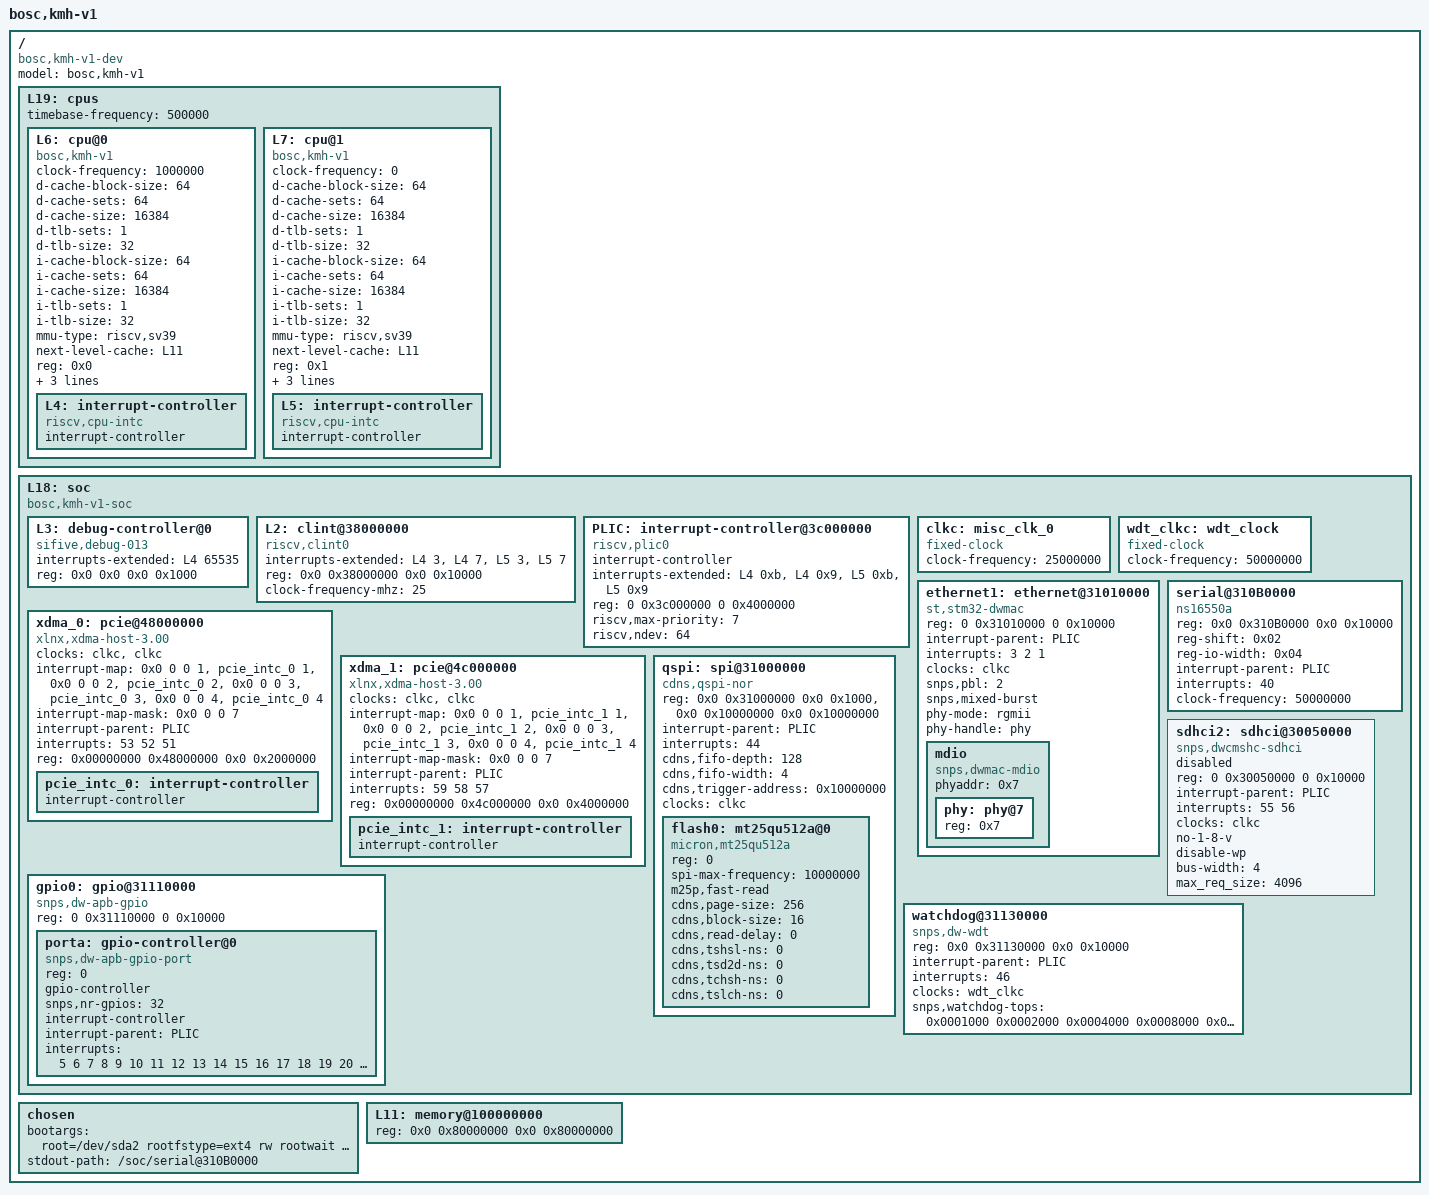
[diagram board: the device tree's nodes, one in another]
// SPDX-License-Identifier: (GPL-2.0 OR MIT)
/* Copyright (c) 2023-2024 BOSC */

/dts-v1/;

/ {
	#address-cells = <2>;
	#size-cells = <2>;
	compatible = "bosc,kmh-v1-dev";
	model = "bosc,kmh-v1";

	L19: cpus {
		#address-cells = <1>;
		#size-cells = <0>;
		timebase-frequency = <500000>;//50Khz

		L6: cpu@0 {
			clock-frequency = <1000000>;
			compatible = "bosc,kmh-v1", "riscv";
			d-cache-block-size = <64>;
			d-cache-sets = <64>;
			d-cache-size = <16384>;
			d-tlb-sets = <1>;
			d-tlb-size = <32>;
			device_type = "cpu";
			i-cache-block-size = <64>;
			i-cache-sets = <64>;
			i-cache-size = <16384>;
			i-tlb-sets = <1>;
			i-tlb-size = <32>;
			mmu-type = "riscv,sv39";
			next-level-cache = <&L11>;
			reg = <0x0>;
			riscv,isa = "rv64imafdc";
			status = "okay";
			timebase-frequency = <500000>;//50Khz
			tlb-split;

			L4: interrupt-controller {
				#interrupt-cells = <1>;
				compatible = "riscv,cpu-intc";
				interrupt-controller;
			};
		};

		L7: cpu@1 {
			clock-frequency = <0>;
			compatible = "bosc,kmh-v1", "riscv";
			d-cache-block-size = <64>;
			d-cache-sets = <64>;
			d-cache-size = <16384>;
			d-tlb-sets = <1>;
			d-tlb-size = <32>;
			device_type = "cpu";
			i-cache-block-size = <64>;
			i-cache-sets = <64>;
			i-cache-size = <16384>;
			i-tlb-sets = <1>;
			i-tlb-size = <32>;
			mmu-type = "riscv,sv39";
			next-level-cache = <&L11>;
			reg = <0x1>;
			riscv,isa = "rv64imafdc";
			status = "okay";
			timebase-frequency = <500000>;//50Khz
			tlb-split;

			L5: interrupt-controller {
				#interrupt-cells = <1>;
				compatible = "riscv,cpu-intc";
				interrupt-controller;
			};
		};

	};

	L18: soc {
		#address-cells = <2>;
		#size-cells = <2>;
		compatible = "bosc,kmh-v1-soc", "simple-bus";
		ranges;

		L3: debug-controller@0 {
			compatible = "sifive,debug-013", "riscv,debug-013";
			interrupts-extended = <&L4 65535>;
			reg = <0x0 0x0 0x0 0x1000>;
			reg-names = "control";
		};

		L2: clint@38000000 {
			compatible = "riscv,clint0";
			interrupts-extended = <&L4 3 &L4 7 &L5 3 &L5 7>;
			reg = <0x0 0x38000000 0x0 0x10000>;
			reg-names = "control";
			clock-frequency-mhz = <25>;
		};

		PLIC: interrupt-controller@3c000000 {
			#interrupt-cells = <1>;
			compatible = "riscv,plic0";
			interrupt-controller;
			interrupts-extended = <&L4 0xb &L4 0x9 &L5 0xb &L5 0x9>;
			reg = <0 0x3c000000 0 0x4000000>;
			reg-names = "control";
			riscv,max-priority = <7>;
			riscv,ndev = <64>;
		};

		clkc: misc_clk_0 {
			#clock-cells = <0>;
			clock-frequency = <25000000>;
			compatible = "fixed-clock";
		};

		wdt_clkc: wdt_clock{
			#clock-cells = <0>;
			clock-frequency = <50000000>;
			compatible = "fixed-clock";
		};

		ethernet1: ethernet@31010000 {
			compatible = "st,stm32-dwmac", "snps,dwmac-3.50a";
			reg = <0 0x31010000 0 0x10000>;
			reg-names = "stmmaceth";
			interrupt-parent = <&PLIC>;
			interrupts = <3 2 1>;
			interrupt-names = "eth_lpi", "macirq", "eth_wake_irq";
			clock-names = "stmmaceth";
			clocks = <&clkc>;
			snps,pbl = <2>;
			snps,mixed-burst;
			phy-mode = "rgmii";
			// stmmac driver can not find phy if add this node
			//
			phy-handle = <&phy>;

			mdio {
				#address-cells = <0x1>;
				#size-cells = <0x0>;
				phyaddr = <0x7>;
				compatible = "snps,dwmac-mdio";

				phy: phy@7 {
					//phyaddr = <0x7>;
					//compatible = "marvell,88e1116r";
					//device_type = "ethernet-phy";
					reg = <0x7>;
				};
			};
		};

		xdma_0: pcie@48000000 {
				#address-cells = <3>;
				#interrupt-cells = <1>;
				#size-cells = <2>;
				clock-names = "sys_clk", "sys_clk_gt";
				clocks = <&clkc>, <&clkc>;
				compatible = "xlnx,xdma-host-3.00";
				device_type = "pci";
				interrupt-map =	<0x0 0 0 1 &pcie_intc_0 1>,
						<0x0 0 0 2 &pcie_intc_0 2>,
						<0x0 0 0 3 &pcie_intc_0 3>,
						<0x0 0 0 4 &pcie_intc_0 4>;
				interrupt-map-mask = <0x0 0 0 7>;
				interrupt-names = "misc", "msi0", "msi1";
				interrupt-parent = <&PLIC>;
				interrupts = <53 52 51>;
				//bus-range = <0x00 0xff>;
				ranges = <0x02000000 0x00000000 0x20000000 0x0 0x40000000 0x00000000 0x8000000>;
				reg = <0x00000000 0x48000000 0x0 0x2000000>;

				pcie_intc_0: interrupt-controller {
					#address-cells = <0>;
					#interrupt-cells = <1>;
					interrupt-controller ;
				};
		};

		xdma_1: pcie@4c000000 {
			#address-cells = <3>;
			#interrupt-cells = <1>;
			#size-cells = <2>;
			clock-names = "sys_clk", "sys_clk_gt";
			clocks = <&clkc>, <&clkc>;
			compatible = "xlnx,xdma-host-3.00";
			device_type = "pci";
			interrupt-map =	<0x0 0 0 1 &pcie_intc_1 1>,
					<0x0 0 0 2 &pcie_intc_1 2>,
					<0x0 0 0 3 &pcie_intc_1 3>,
					<0x0 0 0 4 &pcie_intc_1 4>;
			interrupt-map-mask = <0x0 0 0 7>;
			interrupt-names = "misc", "msi0", "msi1";
			interrupt-parent = <&PLIC>;
			interrupts = <59 58 57>;
			//bus-range = <0x00 0xff>;
			ranges = <0x02000000 0x0 0x40000000 0x0 0x60000000 0x00000000 0x20000000>;
			reg = <0x00000000 0x4c000000 0x0 0x4000000>;

			pcie_intc_1:interrupt-controller {
				#address-cells = <0>; 
				#interrupt-cells = <1>;
				interrupt-controller;
			};
		};

		serial@310B0000 {
			compatible = "ns16550a";
			reg = <0x0 0x310B0000 0x0 0x10000>;
			reg-shift = <0x02>;
			reg-io-width = <0x04>;
			interrupt-parent = <&PLIC>;
			interrupts = <40>;
			clock-frequency = <50000000>;
			status = "okay";
		};

		qspi: spi@31000000 {
			compatible = "cdns,qspi-nor";
			#address-cells = <1>;
			#size-cells = <0>;
			reg = <0x0 0x31000000 0x0 0x1000>,
			      <0x0 0x10000000 0x0 0x10000000>;
			interrupt-parent = <&PLIC>;
			interrupts = <44>;
			cdns,fifo-depth = <128>;
			cdns,fifo-width = <4>;
			cdns,trigger-address = <0x10000000>;
			clocks = <&clkc>;
			status = "okay";

			flash0: mt25qu512a@0 {
				#address-cells = <1>;
				#size-cells = <1>;
				compatible = "micron,mt25qu512a", "jedec,spi-nor";
				reg = <0>;	/* chip select */
				spi-max-frequency = <10000000>;
				m25p,fast-read;
				cdns,page-size = <256>;
				cdns,block-size = <16>;
				cdns,read-delay = <0>;
				cdns,tshsl-ns = <0>;
				cdns,tsd2d-ns = <0>;
				cdns,tchsh-ns = <0>;
				cdns,tslch-ns = <0>;
			};
		};

		sdhci2: sdhci@30050000 {
			compatible = "snps,dwcmshc-sdhci";
			reg = <0 0x30050000 0 0x10000>;
			interrupt-parent = <&PLIC>;
			interrupts = <55 56>;
			clocks = <&clkc>;
			clock-names = "core";
			//sd-uhs-sdr12;
			no-1-8-v;
			disable-wp;
			bus-width = <4>;
			max_req_size = <4096>;
			status = "disabled";
		};

		gpio0: gpio@31110000 {
			compatible = "snps,dw-apb-gpio";
			reg = <0 0x31110000 0 0x10000>;
			#address-cells = <1>;
			#size-cells = <0>;

			porta: gpio-controller@0 {
				compatible = "snps,dw-apb-gpio-port";
				reg = <0>;
				gpio-controller;
				#gpio-cells = <2>;
				snps,nr-gpios = <32>;
				interrupt-controller;
				interrupt-parent = <&PLIC>;
				interrupts =
					<5  6  7  8  9  10 11 12
					13 14 15 16 17 18 19 20
					21 22 23 24 25 26 27 28
					29 30 31 32 33 34 35 36>;
			};
		};

		watchdog@31130000 {
			compatible = "snps,dw-wdt";
			reg = <0x0 0x31130000 0x0 0x10000>;
			interrupt-parent = <&PLIC>;
			interrupts = <46>;
			clocks = <&wdt_clkc>;
			snps,watchdog-tops =
				<0x0001000 0x0002000 0x0004000 0x0008000
				0x0010000 0x0020000 0x0040000 0x0080000
				0x0100000 0x0200000 0x0400000 0x0800000
				0x1000000 0x2000000 0x4000000 0x8000000>;
		};
	};

	chosen {
		bootargs = "root=/dev/sda2 rootfstype=ext4 rw rootwait console=ttyS0,115200n8 earlycon noinitrd";
		stdout-path = "/soc/serial@310B0000";
	};

	L11: memory@100000000 {
		device_type = "memory";
		reg = <0x0 0x80000000 0x0 0x80000000>;
	};
};
